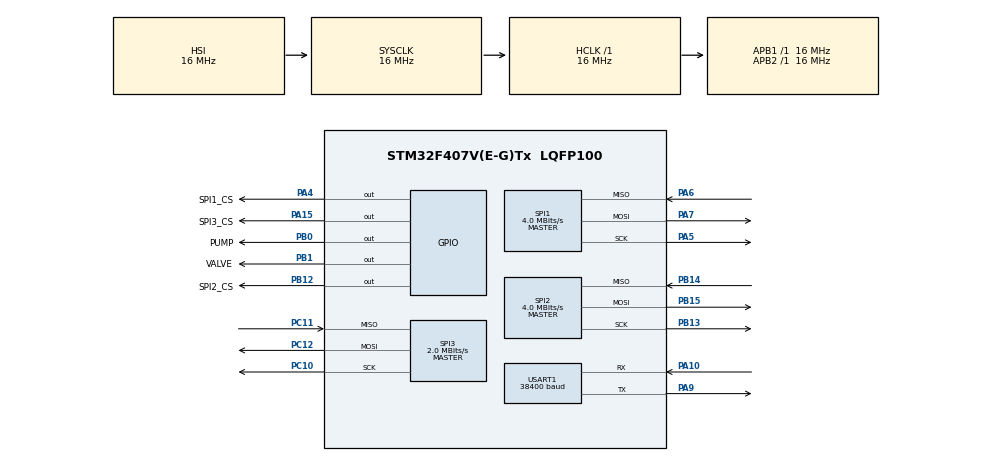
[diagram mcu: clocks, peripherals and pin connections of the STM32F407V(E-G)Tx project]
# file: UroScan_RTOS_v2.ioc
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Dma.Request0=USART1_RX
Dma.Request1=USART1_TX
Dma.Request2=SPI2_RX
Dma.SPI2_RX.2.Direction=DMA_PERIPH_TO_MEMORY
Dma.SPI2_RX.2.FIFOMode=DMA_FIFOMODE_DISABLE
Dma.SPI2_RX.2.Instance=DMA1_Stream3
Dma.SPI2_RX.2.MemDataAlignment=DMA_MDATAALIGN_BYTE
Dma.SPI2_RX.2.MemInc=DMA_MINC_ENABLE
Dma.SPI2_RX.2.Mode=DMA_NORMAL
Dma.SPI2_RX.2.PeriphDataAlignment=DMA_PDATAALIGN_BYTE
Dma.SPI2_RX.2.PeriphInc=DMA_PINC_DISABLE
Dma.SPI2_RX.2.Priority=DMA_PRIORITY_LOW
Dma.USART1_RX.0.Direction=DMA_PERIPH_TO_MEMORY
Dma.USART1_RX.0.FIFOMode=DMA_FIFOMODE_DISABLE
Dma.USART1_RX.0.Instance=DMA2_Stream2
Dma.USART1_RX.0.MemDataAlignment=DMA_MDATAALIGN_BYTE
Dma.USART1_RX.0.MemInc=DMA_MINC_ENABLE
Dma.USART1_RX.0.Mode=DMA_NORMAL
Dma.USART1_RX.0.PeriphDataAlignment=DMA_PDATAALIGN_BYTE
Dma.USART1_RX.0.PeriphInc=DMA_PINC_DISABLE
Dma.USART1_RX.0.Priority=DMA_PRIORITY_LOW
Dma.USART1_TX.1.Direction=DMA_MEMORY_TO_PERIPH
Dma.USART1_TX.1.FIFOMode=DMA_FIFOMODE_DISABLE
Dma.USART1_TX.1.Instance=DMA2_Stream7
Dma.USART1_TX.1.MemDataAlignment=DMA_MDATAALIGN_BYTE
Dma.USART1_TX.1.MemInc=DMA_MINC_ENABLE
Dma.USART1_TX.1.Mode=DMA_NORMAL
Dma.USART1_TX.1.PeriphDataAlignment=DMA_PDATAALIGN_BYTE
Dma.USART1_TX.1.PeriphInc=DMA_PINC_DISABLE
Dma.USART1_TX.1.Priority=DMA_PRIORITY_LOW
FREERTOS.Tasks01=defaultTask,24,128,StartDefaultTask,Default,NULL,Dynamic,NULL,NULL
Mcu.Family=STM32F4
Mcu.Name=STM32F407V(E-G)Tx
Mcu.Package=LQFP100
NVIC.DMA1_Stream3_IRQn=true\:5\:0\:false\:false\:true\:true\:false\:true\:true
NVIC.DMA2_Stream2_IRQn=true\:5\:0\:false\:false\:true\:true\:false\:true\:true
NVIC.DMA2_Stream7_IRQn=true\:5\:0\:false\:false\:true\:true\:false\:true\:true
NVIC.PriorityGroup=NVIC_PRIORITYGROUP_4
NVIC.TIM1_TRG_COM_TIM11_IRQn=true\:5\:0\:false\:false\:true\:true\:true\:true\:true
NVIC.USART1_IRQn=true\:5\:0\:false\:false\:true\:true\:true\:true\:true
PA10.Mode=Asynchronous
PA10.Signal=USART1_RX
PA13.Mode=Serial_Wire
PA13.Signal=SYS_JTMS-SWDIO
PA14.Mode=Serial_Wire
PA14.Signal=SYS_JTCK-SWCLK
PA15.GPIO_Label=SPI3_CS
PA15.Signal=GPIO_Output
PA4.GPIO_Label=SPI1_CS
PA4.Signal=GPIO_Output
PA5.Mode=Full_Duplex_Master
PA5.Signal=SPI1_SCK
PA6.Mode=Full_Duplex_Master
PA6.Signal=SPI1_MISO
PA7.Mode=Full_Duplex_Master
PA7.Signal=SPI1_MOSI
PA9.Mode=Asynchronous
PA9.Signal=USART1_TX
PB0.GPIO_Label=PUMP
PB0.Signal=GPIO_Output
PB1.GPIO_Label=VALVE
PB1.Signal=GPIO_Output
PB12.GPIO_Label=SPI2_CS
PB12.Signal=GPIO_Output
PB13.Mode=Full_Duplex_Master
PB13.Signal=SPI2_SCK
PB14.Mode=Full_Duplex_Master
PB14.Signal=SPI2_MISO
PB15.Mode=Full_Duplex_Master
PB15.Signal=SPI2_MOSI
PC10.Mode=Full_Duplex_Master
PC10.Signal=SPI3_SCK
PC11.Mode=Full_Duplex_Master
PC11.Signal=SPI3_MISO
PC12.Mode=Full_Duplex_Master
PC12.Signal=SPI3_MOSI
PH0-OSC_IN.Mode=HSE-External-Oscillator
PH0-OSC_IN.Signal=RCC_OSC_IN
PH1-OSC_OUT.Mode=HSE-External-Oscillator
PH1-OSC_OUT.Signal=RCC_OSC_OUT
ProjectManager.HeapSize=0x200
ProjectManager.StackSize=0x400
ProjectManager.TargetToolchain=STM32CubeIDE
RCC.AHBFreq_Value=16000000
RCC.APB1Freq_Value=16000000
RCC.APB2Freq_Value=16000000
RCC.CortexFreq_Value=16000000
RCC.HSE_VALUE=25000000
RCC.HSI_VALUE=16000000
RCC.LSE_VALUE=32768
RCC.SYSCLKFreq_VALUE=16000000
RCC.VCOOutputFreq_Value=192000000
SPI1.BaudRatePrescaler=SPI_BAUDRATEPRESCALER_4
SPI1.CalculateBaudRate=4.0 MBits/s
SPI1.Direction=SPI_DIRECTION_2LINES
SPI1.Mode=SPI_MODE_MASTER
SPI1.VirtualType=VM_MASTER
SPI2.BaudRatePrescaler=SPI_BAUDRATEPRESCALER_4
SPI2.CalculateBaudRate=4.0 MBits/s
SPI2.Direction=SPI_DIRECTION_2LINES
SPI2.Mode=SPI_MODE_MASTER
SPI2.VirtualType=VM_MASTER
SPI3.BaudRatePrescaler=SPI_BAUDRATEPRESCALER_8
SPI3.CalculateBaudRate=2.0 MBits/s
SPI3.Direction=SPI_DIRECTION_2LINES
SPI3.Mode=SPI_MODE_MASTER
SPI3.VirtualType=VM_MASTER
TIM11.Period=99
TIM11.Prescaler=16
USART1.BaudRate=38400
USART1.VirtualMode=VM_ASYNC
VP_FREERTOS_VS_CMSIS_V2.Mode=CMSIS_V2
VP_TIM11_VS_ClockSourceINT.Mode=Enable_Timer
board=custom

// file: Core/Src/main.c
/* USER CODE BEGIN Header */
/**
  ******************************************************************************
  * @file           : main.c
  * @brief          : Main program body
  ******************************************************************************
  * @attention
  *
  * Copyright (c) 2024 STMicroelectronics.
  * All rights reserved.
  *
  * This software is licensed under terms that can be found in the LICENSE file
  * in the root directory of this software component.
  * If no LICENSE file comes with this software, it is provided AS-IS.
  *
  ******************************************************************************
  */
/* USER CODE END Header */
#include "main.h"
#include "cmsis_os.h"

/* USER CODE BEGIN Includes */
#include "../../User/Inc/SystemAdapter.h"
#include "string.h"
/* USER CODE END Includes */

SPI_HandleTypeDef hspi1;
SPI_HandleTypeDef hspi2;
SPI_HandleTypeDef hspi3;
DMA_HandleTypeDef hdma_spi1_rx;
DMA_HandleTypeDef hdma_spi1_tx;
DMA_HandleTypeDef hdma_spi2_rx;
DMA_HandleTypeDef hdma_spi2_tx;
DMA_HandleTypeDef hdma_spi3_rx;
DMA_HandleTypeDef hdma_spi3_tx;

TIM_HandleTypeDef htim11;

UART_HandleTypeDef huart1;
DMA_HandleTypeDef hdma_usart1_rx;
DMA_HandleTypeDef hdma_usart1_tx;

/* Definitions for defaultTask */
osThreadId_t defaultTaskHandle;
const osThreadAttr_t defaultTask_attributes = {
  .name = "defaultTask",
  .stack_size = 128 * 4,
  .priority = (osPriority_t) osPriorityNormal,
};

void SystemClock_Config(void);
static void MX_GPIO_Init(void);
static void MX_DMA_Init(void);
static void MX_SPI1_Init(void);
static void MX_SPI2_Init(void);
static void MX_SPI3_Init(void);
static void MX_USART1_UART_Init(void);
static void MX_TIM11_Init(void);
void StartDefaultTask(void *argument);

int main(void)
{

  /* MCU Configuration--------------------------------------------------------*/

  /* Reset of all peripherals, Initializes the Flash interface and the Systick. */
  HAL_Init();

  /* Configure the system clock */
  SystemClock_Config();

  /* Initialize all configured peripherals */
  MX_GPIO_Init();
  MX_DMA_Init();
  MX_SPI1_Init();
  MX_SPI2_Init();
  MX_SPI3_Init();
  MX_USART1_UART_Init();
  MX_TIM11_Init();
  /* USER CODE BEGIN 2 */
	  SetupOS();
	  StartOS();
	  return 0;
  /* USER CODE END 2 */

  /* Init scheduler */
  osKernelInitialize();

  /* Create the thread(s) */
  /* Created of defaultTask */
  defaultTaskHandle = osThreadNew(StartDefaultTask, NULL, &defaultTask_attributes);

  /* Start scheduler */
  osKernelStart();

  /* We should never get here as control is now taken by the scheduler */

  /* Infinite loop */
  while (1)
  {

  }
}

void SystemClock_Config(void)
{
  RCC_OscInitTypeDef RCC_OscInitStruct = {0};
  RCC_ClkInitTypeDef RCC_ClkInitStruct = {0};

  /** Configure the main internal regulator output voltage
  */
  __HAL_RCC_PWR_CLK_ENABLE();
  __HAL_PWR_VOLTAGESCALING_CONFIG(PWR_REGULATOR_VOLTAGE_SCALE1);

  /** Initializes the RCC Oscillators according to the specified parameters
  * in the RCC_OscInitTypeDef structure.
  */
  RCC_OscInitStruct.OscillatorType = RCC_OSCILLATORTYPE_HSI;
  RCC_OscInitStruct.HSIState = RCC_HSI_ON;
  RCC_OscInitStruct.HSICalibrationValue = RCC_HSICALIBRATION_DEFAULT;
  RCC_OscInitStruct.PLL.PLLState = RCC_PLL_NONE;
  if (HAL_RCC_OscConfig(&RCC_OscInitStruct) != HAL_OK)
  {
    Error_Handler();
  }

  /** Initializes the CPU, AHB and APB buses clocks
  */
  RCC_ClkInitStruct.ClockType = RCC_CLOCKTYPE_HCLK|RCC_CLOCKTYPE_SYSCLK
                              |RCC_CLOCKTYPE_PCLK1|RCC_CLOCKTYPE_PCLK2;
  RCC_ClkInitStruct.SYSCLKSource = RCC_SYSCLKSOURCE_HSI;
  RCC_ClkInitStruct.AHBCLKDivider = RCC_SYSCLK_DIV1;
  RCC_ClkInitStruct.APB1CLKDivider = RCC_HCLK_DIV1;
  RCC_ClkInitStruct.APB2CLKDivider = RCC_HCLK_DIV1;

  if (HAL_RCC_ClockConfig(&RCC_ClkInitStruct, FLASH_LATENCY_0) != HAL_OK)
  {
    Error_Handler();
  }
}

static void MX_SPI1_Init(void)
{

  /* SPI1 parameter configuration*/
  hspi1.Instance = SPI1;
  hspi1.Init.Mode = SPI_MODE_MASTER;
  hspi1.Init.Direction = SPI_DIRECTION_2LINES;
  hspi1.Init.DataSize = SPI_DATASIZE_8BIT;
  hspi1.Init.CLKPolarity = SPI_POLARITY_LOW;
  hspi1.Init.CLKPhase = SPI_PHASE_1EDGE;
  hspi1.Init.NSS = SPI_NSS_SOFT;
  hspi1.Init.BaudRatePrescaler = SPI_BAUDRATEPRESCALER_4;
  hspi1.Init.FirstBit = SPI_FIRSTBIT_MSB;
  hspi1.Init.TIMode = SPI_TIMODE_DISABLE;
  hspi1.Init.CRCCalculation = SPI_CRCCALCULATION_DISABLE;
  hspi1.Init.CRCPolynomial = 10;
  if (HAL_SPI_Init(&hspi1) != HAL_OK)
  {
    Error_Handler();
  }

}

static void MX_SPI2_Init(void)
{

  /* SPI2 parameter configuration*/
  hspi2.Instance = SPI2;
  hspi2.Init.Mode = SPI_MODE_MASTER;
  hspi2.Init.Direction = SPI_DIRECTION_2LINES;
  hspi2.Init.DataSize = SPI_DATASIZE_8BIT;
  hspi2.Init.CLKPolarity = SPI_POLARITY_LOW;
  hspi2.Init.CLKPhase = SPI_PHASE_1EDGE;
  hspi2.Init.NSS = SPI_NSS_SOFT;
  hspi2.Init.BaudRatePrescaler = SPI_BAUDRATEPRESCALER_4;
  hspi2.Init.FirstBit = SPI_FIRSTBIT_MSB;
  hspi2.Init.TIMode = SPI_TIMODE_DISABLE;
  hspi2.Init.CRCCalculation = SPI_CRCCALCULATION_DISABLE;
  hspi2.Init.CRCPolynomial = 10;
  if (HAL_SPI_Init(&hspi2) != HAL_OK)
  {
    Error_Handler();
  }

}

static void MX_SPI3_Init(void)
{

  /* SPI3 parameter configuration*/
  hspi3.Instance = SPI3;
  hspi3.Init.Mode = SPI_MODE_MASTER;
  hspi3.Init.Direction = SPI_DIRECTION_2LINES;
  hspi3.Init.DataSize = SPI_DATASIZE_8BIT;
  hspi3.Init.CLKPolarity = SPI_POLARITY_LOW;
  hspi3.Init.CLKPhase = SPI_PHASE_1EDGE;
  hspi3.Init.NSS = SPI_NSS_SOFT;
  hspi3.Init.BaudRatePrescaler = SPI_BAUDRATEPRESCALER_8;
  hspi3.Init.FirstBit = SPI_FIRSTBIT_MSB;
  hspi3.Init.TIMode = SPI_TIMODE_DISABLE;
  hspi3.Init.CRCCalculation = SPI_CRCCALCULATION_DISABLE;
  hspi3.Init.CRCPolynomial = 10;
  if (HAL_SPI_Init(&hspi3) != HAL_OK)
  {
    Error_Handler();
  }

}

static void MX_TIM11_Init(void)
{

  htim11.Instance = TIM11;
  htim11.Init.Prescaler = 16;
  htim11.Init.CounterMode = TIM_COUNTERMODE_UP;
  htim11.Init.Period = 99;
  htim11.Init.ClockDivision = TIM_CLOCKDIVISION_DIV1;
  htim11.Init.AutoReloadPreload = TIM_AUTORELOAD_PRELOAD_DISABLE;
  if (HAL_TIM_Base_Init(&htim11) != HAL_OK)
  {
    Error_Handler();
  }

}

static void MX_USART1_UART_Init(void)
{

  huart1.Instance = USART1;
  huart1.Init.BaudRate = 38400;
  huart1.Init.WordLength = UART_WORDLENGTH_8B;
  huart1.Init.StopBits = UART_STOPBITS_1;
  huart1.Init.Parity = UART_PARITY_NONE;
  huart1.Init.Mode = UART_MODE_TX_RX;
  huart1.Init.HwFlowCtl = UART_HWCONTROL_NONE;
  huart1.Init.OverSampling = UART_OVERSAMPLING_16;
  if (HAL_UART_Init(&huart1) != HAL_OK)
  {
    Error_Handler();
  }

}

static void MX_DMA_Init(void)
{

  /* DMA controller clock enable */
  __HAL_RCC_DMA2_CLK_ENABLE();
  __HAL_RCC_DMA1_CLK_ENABLE();

  /* DMA interrupt init */
  /* DMA1_Stream0_IRQn interrupt configuration */
  HAL_NVIC_SetPriority(DMA1_Stream0_IRQn, 5, 0);
  HAL_NVIC_EnableIRQ(DMA1_Stream0_IRQn);
  /* DMA1_Stream3_IRQn interrupt configuration */
  HAL_NVIC_SetPriority(DMA1_Stream3_IRQn, 5, 0);
  HAL_NVIC_EnableIRQ(DMA1_Stream3_IRQn);
  /* DMA1_Stream4_IRQn interrupt configuration */
  HAL_NVIC_SetPriority(DMA1_Stream4_IRQn, 5, 0);
  HAL_NVIC_EnableIRQ(DMA1_Stream4_IRQn);
  /* DMA1_Stream5_IRQn interrupt configuration */
  HAL_NVIC_SetPriority(DMA1_Stream5_IRQn, 5, 0);
  HAL_NVIC_EnableIRQ(DMA1_Stream5_IRQn);
  /* DMA2_Stream0_IRQn interrupt configuration */
  HAL_NVIC_SetPriority(DMA2_Stream0_IRQn, 5, 0);
  HAL_NVIC_EnableIRQ(DMA2_Stream0_IRQn);
  /* DMA2_Stream2_IRQn interrupt configuration */
  HAL_NVIC_SetPriority(DMA2_Stream2_IRQn, 5, 0);
  HAL_NVIC_EnableIRQ(DMA2_Stream2_IRQn);
  /* DMA2_Stream3_IRQn interrupt configuration */
  HAL_NVIC_SetPriority(DMA2_Stream3_IRQn, 5, 0);
  HAL_NVIC_EnableIRQ(DMA2_Stream3_IRQn);
  /* DMA2_Stream7_IRQn interrupt configuration */
  HAL_NVIC_SetPriority(DMA2_Stream7_IRQn, 5, 0);
  HAL_NVIC_EnableIRQ(DMA2_Stream7_IRQn);

}

static void MX_GPIO_Init(void)
{
  GPIO_InitTypeDef GPIO_InitStruct = {0};

  /* GPIO Ports Clock Enable */
  __HAL_RCC_GPIOH_CLK_ENABLE();
  __HAL_RCC_GPIOA_CLK_ENABLE();
  __HAL_RCC_GPIOB_CLK_ENABLE();
  __HAL_RCC_GPIOC_CLK_ENABLE();

  /*Configure GPIO pin Output Level */
  HAL_GPIO_WritePin(GPIOA, SPI1_CS_Pin|SPI3_CS_Pin, GPIO_PIN_RESET);

  /*Configure GPIO pin Output Level */
  HAL_GPIO_WritePin(GPIOB, PUMP_Pin|VALVE_Pin|SPI2_CS_Pin, GPIO_PIN_RESET);

  /*Configure GPIO pins : SPI1_CS_Pin SPI3_CS_Pin */
  GPIO_InitStruct.Pin = SPI1_CS_Pin|SPI3_CS_Pin;
  GPIO_InitStruct.Mode = GPIO_MODE_OUTPUT_PP;
  GPIO_InitStruct.Pull = GPIO_NOPULL;
  GPIO_InitStruct.Speed = GPIO_SPEED_FREQ_LOW;
  HAL_GPIO_Init(GPIOA, &GPIO_InitStruct);

  /*Configure GPIO pins : PUMP_Pin VALVE_Pin SPI2_CS_Pin */
  GPIO_InitStruct.Pin = PUMP_Pin|VALVE_Pin|SPI2_CS_Pin;
  GPIO_InitStruct.Mode = GPIO_MODE_OUTPUT_PP;
  GPIO_InitStruct.Pull = GPIO_NOPULL;
  GPIO_InitStruct.Speed = GPIO_SPEED_FREQ_LOW;
  HAL_GPIO_Init(GPIOB, &GPIO_InitStruct);

}

void StartDefaultTask(void *argument)
{
  for(;;)
  {
    osDelay(1);
  }
}

void Error_Handler(void)
{
  __disable_irq();
  while (1)
  {
  }
}
